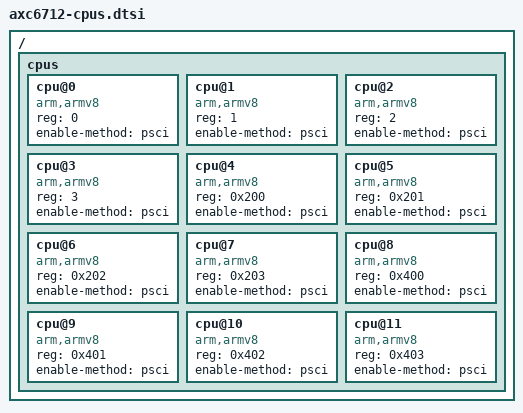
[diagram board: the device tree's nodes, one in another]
// SPDX-License-Identifier: GPL-2.0
// Copyright (C) 2021 INTEL Corporation

/ {
	cpus {
		#address-cells = <1>;
		#size-cells = <0>;

		cpu@0 {
			device_type = "cpu";
			compatible = "arm,armv8";
			reg = <0>;
			enable-method = "psci";
		};

		cpu@1 {
			device_type = "cpu";
			compatible = "arm,armv8";
			reg = <1>;
			enable-method = "psci";
		};

		cpu@2 {
			device_type = "cpu";
			compatible = "arm,armv8";
			reg = <2>;
			enable-method = "psci";
		};

		cpu@3 {
			device_type = "cpu";
			compatible = "arm,armv8";
			reg = <3>;
			enable-method = "psci";
		};

		cpu@4 {
			device_type = "cpu";
			compatible = "arm,armv8";
			reg = <0x200>;
			enable-method = "psci";
		};

		cpu@5 {
			device_type = "cpu";
			compatible = "arm,armv8";
			reg = <0x201>;
			enable-method = "psci";
		};

		cpu@6 {
			device_type = "cpu";
			compatible = "arm,armv8";
			reg = <0x202>;
			enable-method = "psci";
		};

		cpu@7 {
			device_type = "cpu";
			compatible = "arm,armv8";
			reg = <0x203>;
			enable-method = "psci";

		};

		cpu@8 {
			device_type = "cpu";
			compatible = "arm,armv8";
			reg = <0x400>;
			enable-method = "psci";
		};

		cpu@9 {
			device_type = "cpu";
			compatible = "arm,armv8";
			reg = <0x401>;
			enable-method = "psci";
		};

		cpu@10 {
			device_type = "cpu";
			compatible = "arm,armv8";
			reg = <0x402>;
			enable-method = "psci";
		};

		cpu@11 {
			device_type = "cpu";
			compatible = "arm,armv8";
			reg = <0x403>;
			enable-method = "psci";

		};
	};
};
